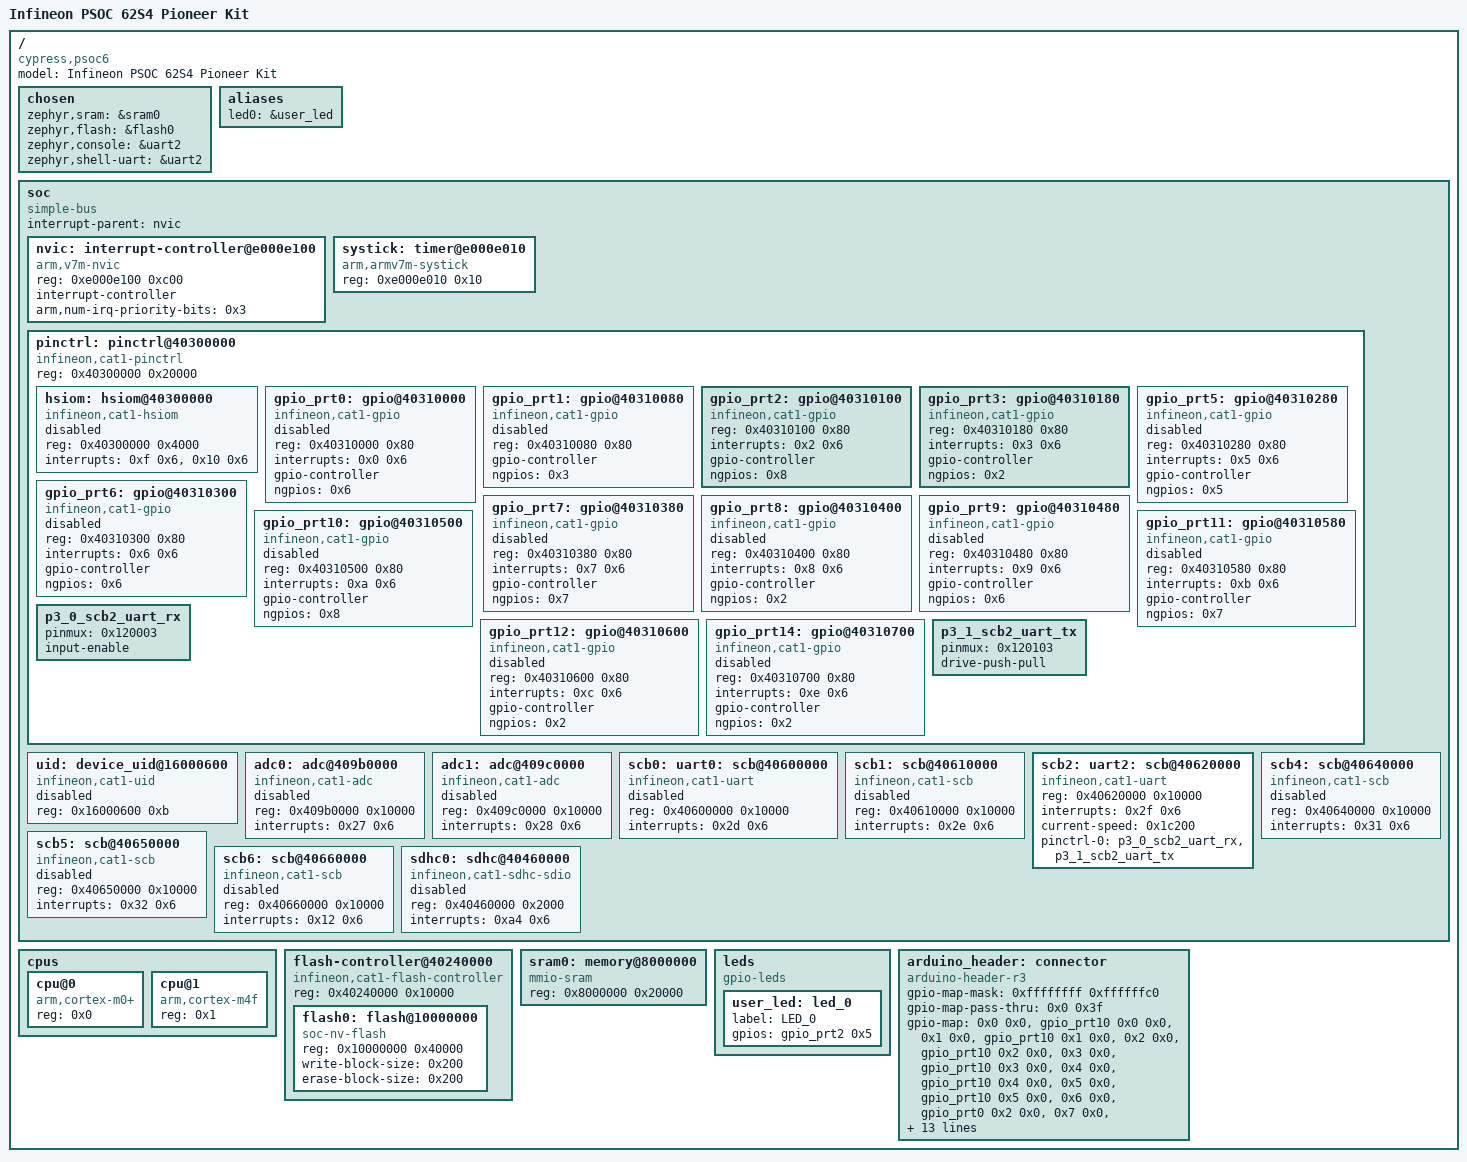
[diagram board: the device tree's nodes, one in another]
/dts-v1/;

/* node '/' defined in zephyr/dts/common/skeleton.dtsi:9 */
/ {
	#address-cells = < 0x1 >;                 /* in zephyr/dts/common/skeleton.dtsi:10 */
	#size-cells = < 0x1 >;                    /* in zephyr/dts/common/skeleton.dtsi:11 */
	model = "Infineon PSOC 62S4 Pioneer Kit"; /* in zephyr/boards/infineon/cy8ckit_062s4/cy8ckit_062s4.dts:11 */
	compatible = "cypress,psoc6";             /* in zephyr/boards/infineon/cy8ckit_062s4/cy8ckit_062s4.dts:12 */

	/* node '/chosen' defined in zephyr/dts/common/skeleton.dtsi:13 */
	chosen {
		zephyr,sram = &sram0;       /* in zephyr/boards/infineon/cy8ckit_062s4/cy8ckit_062s4.dts:15 */
		zephyr,flash = &flash0;     /* in zephyr/boards/infineon/cy8ckit_062s4/cy8ckit_062s4.dts:16 */
		zephyr,console = &uart2;    /* in zephyr/boards/infineon/cy8ckit_062s4/cy8ckit_062s4.dts:17 */
		zephyr,shell-uart = &uart2; /* in zephyr/boards/infineon/cy8ckit_062s4/cy8ckit_062s4.dts:18 */
	};

	/* node '/aliases' defined in zephyr/dts/common/skeleton.dtsi:15 */
	aliases {
		led0 = &user_led; /* in zephyr/boards/infineon/cy8ckit_062s4/cy8ckit_062s4.dts:22 */
	};

	/* node '/soc' defined in zephyr/dts/arm/armv7-m.dtsi:6 */
	soc {
		#address-cells = < 0x1 >;     /* in zephyr/dts/arm/armv7-m.dtsi:7 */
		#size-cells = < 0x1 >;        /* in zephyr/dts/arm/armv7-m.dtsi:8 */
		compatible = "simple-bus";    /* in zephyr/dts/arm/armv7-m.dtsi:9 */
		interrupt-parent = < &nvic >; /* in zephyr/dts/arm/armv7-m.dtsi:10 */
		ranges;                       /* in zephyr/dts/arm/armv7-m.dtsi:11 */

		/* node '/soc/interrupt-controller@e000e100' defined in zephyr/dts/arm/armv7-m.dtsi:13 */
		nvic: interrupt-controller@e000e100 {
			#address-cells = < 0x1 >;            /* in zephyr/dts/arm/armv7-m.dtsi:14 */
			compatible = "arm,v7m-nvic";         /* in zephyr/dts/arm/armv7-m.dtsi:15 */
			reg = < 0xe000e100 0xc00 >;          /* in zephyr/dts/arm/armv7-m.dtsi:16 */
			interrupt-controller;                /* in zephyr/dts/arm/armv7-m.dtsi:17 */
			#interrupt-cells = < 0x2 >;          /* in zephyr/dts/arm/armv7-m.dtsi:18 */
			arm,num-irq-priority-bits = < 0x3 >; /* in zephyr/dts/arm/infineon/cat1a/mpns/CY8C6244LQI_S4D92.dtsi:14 */
			phandle = < 0x1 >;                   /* in zephyr/dts/arm/armv7-m.dtsi:10 */
		};

		/* node '/soc/timer@e000e010' defined in zephyr/dts/arm/armv7-m.dtsi:21 */
		systick: timer@e000e010 {
			compatible = "arm,armv7m-systick"; /* in zephyr/dts/arm/armv7-m.dtsi:22 */
			reg = < 0xe000e010 0x10 >;         /* in zephyr/dts/arm/armv7-m.dtsi:23 */
		};

		/* node '/soc/pinctrl@40300000' defined in zephyr/dts/arm/infineon/cat1a/psoc6_04/psoc6_04.dtsi:55 */
		pinctrl: pinctrl@40300000 {
			compatible = "infineon,cat1-pinctrl"; /* in zephyr/dts/arm/infineon/cat1a/psoc6_04/psoc6_04.dtsi:56 */
			reg = < 0x40300000 0x20000 >;         /* in zephyr/dts/arm/infineon/cat1a/psoc6_04/psoc6_04.dtsi:57 */
			#address-cells = < 0x1 >;             /* in zephyr/dts/arm/infineon/cat1a/psoc6_04/psoc6_04.dtsi:58 */
			#size-cells = < 0x0 >;                /* in zephyr/dts/arm/infineon/cat1a/psoc6_04/psoc6_04.dtsi:59 */

			/* node '/soc/pinctrl@40300000/hsiom@40300000' defined in zephyr/dts/arm/infineon/cat1a/psoc6_04/psoc6_04.dtsi:61 */
			hsiom: hsiom@40300000 {
				compatible = "infineon,cat1-hsiom"; /* in zephyr/dts/arm/infineon/cat1a/psoc6_04/psoc6_04.dtsi:62 */
				reg = < 0x40300000 0x4000 >;        /* in zephyr/dts/arm/infineon/cat1a/psoc6_04/psoc6_04.dtsi:63 */
				interrupts = < 0xf 0x6 >,
				             < 0x10 0x6 >;          /* in zephyr/dts/arm/infineon/cat1a/psoc6_04/psoc6_04.dtsi:64 */
				status = "disabled";                /* in zephyr/dts/arm/infineon/cat1a/psoc6_04/psoc6_04.dtsi:65 */
			};

			/* node '/soc/pinctrl@40300000/gpio@40310000' defined in zephyr/dts/arm/infineon/cat1a/psoc6_04/psoc6_04.dtsi:68 */
			gpio_prt0: gpio@40310000 {
				compatible = "infineon,cat1-gpio"; /* in zephyr/dts/arm/infineon/cat1a/psoc6_04/psoc6_04.dtsi:69 */
				reg = < 0x40310000 0x80 >;         /* in zephyr/dts/arm/infineon/cat1a/psoc6_04/psoc6_04.dtsi:70 */
				interrupts = < 0x0 0x6 >;          /* in zephyr/dts/arm/infineon/cat1a/psoc6_04/psoc6_04.dtsi:71 */
				gpio-controller;                   /* in zephyr/dts/arm/infineon/cat1a/psoc6_04/psoc6_04.dtsi:72 */
				ngpios = < 0x6 >;                  /* in zephyr/dts/arm/infineon/cat1a/psoc6_04/psoc6_04.dtsi:73 */
				status = "disabled";               /* in zephyr/dts/arm/infineon/cat1a/psoc6_04/psoc6_04.dtsi:74 */
				#gpio-cells = < 0x2 >;             /* in zephyr/dts/arm/infineon/cat1a/psoc6_04/psoc6_04.dtsi:75 */
				phandle = < 0x6 >;                 /* in zephyr/boards/infineon/cy8ckit_062s4/cy8ckit_062s4.dts:39 */
			};

			/* node '/soc/pinctrl@40300000/gpio@40310080' defined in zephyr/dts/arm/infineon/cat1a/psoc6_04/psoc6_04.dtsi:78 */
			gpio_prt1: gpio@40310080 {
				compatible = "infineon,cat1-gpio"; /* in zephyr/dts/arm/infineon/cat1a/psoc6_04/psoc6_04.dtsi:79 */
				reg = < 0x40310080 0x80 >;         /* in zephyr/dts/arm/infineon/cat1a/psoc6_04/psoc6_04.dtsi:80 */
				gpio-controller;                   /* in zephyr/dts/arm/infineon/cat1a/psoc6_04/psoc6_04.dtsi:81 */
				ngpios = < 0x3 >;                  /* in zephyr/dts/arm/infineon/cat1a/psoc6_04/psoc6_04.dtsi:82 */
				status = "disabled";               /* in zephyr/dts/arm/infineon/cat1a/psoc6_04/psoc6_04.dtsi:83 */
				#gpio-cells = < 0x2 >;             /* in zephyr/dts/arm/infineon/cat1a/psoc6_04/psoc6_04.dtsi:84 */
			};

			/* node '/soc/pinctrl@40300000/gpio@40310100' defined in zephyr/dts/arm/infineon/cat1a/psoc6_04/psoc6_04.dtsi:87 */
			gpio_prt2: gpio@40310100 {
				compatible = "infineon,cat1-gpio"; /* in zephyr/dts/arm/infineon/cat1a/psoc6_04/psoc6_04.dtsi:88 */
				reg = < 0x40310100 0x80 >;         /* in zephyr/dts/arm/infineon/cat1a/psoc6_04/psoc6_04.dtsi:89 */
				interrupts = < 0x2 0x6 >;          /* in zephyr/dts/arm/infineon/cat1a/psoc6_04/psoc6_04.dtsi:90 */
				gpio-controller;                   /* in zephyr/dts/arm/infineon/cat1a/psoc6_04/psoc6_04.dtsi:91 */
				ngpios = < 0x8 >;                  /* in zephyr/dts/arm/infineon/cat1a/psoc6_04/psoc6_04.dtsi:92 */
				#gpio-cells = < 0x2 >;             /* in zephyr/dts/arm/infineon/cat1a/psoc6_04/psoc6_04.dtsi:94 */
				status = "okay";                   /* in zephyr/boards/infineon/cy8ckit_062s4/cy8ckit_062s4.dts:83 */
				phandle = < 0x4 >;                 /* in zephyr/boards/infineon/cy8ckit_062s4/cy8ckit_062s4.dts:30 */
			};

			/* node '/soc/pinctrl@40300000/gpio@40310180' defined in zephyr/dts/arm/infineon/cat1a/psoc6_04/psoc6_04.dtsi:97 */
			gpio_prt3: gpio@40310180 {
				compatible = "infineon,cat1-gpio"; /* in zephyr/dts/arm/infineon/cat1a/psoc6_04/psoc6_04.dtsi:98 */
				reg = < 0x40310180 0x80 >;         /* in zephyr/dts/arm/infineon/cat1a/psoc6_04/psoc6_04.dtsi:99 */
				interrupts = < 0x3 0x6 >;          /* in zephyr/dts/arm/infineon/cat1a/psoc6_04/psoc6_04.dtsi:100 */
				gpio-controller;                   /* in zephyr/dts/arm/infineon/cat1a/psoc6_04/psoc6_04.dtsi:101 */
				ngpios = < 0x2 >;                  /* in zephyr/dts/arm/infineon/cat1a/psoc6_04/psoc6_04.dtsi:102 */
				#gpio-cells = < 0x2 >;             /* in zephyr/dts/arm/infineon/cat1a/psoc6_04/psoc6_04.dtsi:104 */
				status = "okay";                   /* in zephyr/boards/infineon/cy8ckit_062s4/cy8ckit_062s4.dts:79 */
			};

			/* node '/soc/pinctrl@40300000/gpio@40310280' defined in zephyr/dts/arm/infineon/cat1a/psoc6_04/psoc6_04.dtsi:107 */
			gpio_prt5: gpio@40310280 {
				compatible = "infineon,cat1-gpio"; /* in zephyr/dts/arm/infineon/cat1a/psoc6_04/psoc6_04.dtsi:108 */
				reg = < 0x40310280 0x80 >;         /* in zephyr/dts/arm/infineon/cat1a/psoc6_04/psoc6_04.dtsi:109 */
				interrupts = < 0x5 0x6 >;          /* in zephyr/dts/arm/infineon/cat1a/psoc6_04/psoc6_04.dtsi:110 */
				gpio-controller;                   /* in zephyr/dts/arm/infineon/cat1a/psoc6_04/psoc6_04.dtsi:111 */
				ngpios = < 0x5 >;                  /* in zephyr/dts/arm/infineon/cat1a/psoc6_04/psoc6_04.dtsi:112 */
				status = "disabled";               /* in zephyr/dts/arm/infineon/cat1a/psoc6_04/psoc6_04.dtsi:113 */
				#gpio-cells = < 0x2 >;             /* in zephyr/dts/arm/infineon/cat1a/psoc6_04/psoc6_04.dtsi:114 */
				phandle = < 0x7 >;                 /* in zephyr/boards/infineon/cy8ckit_062s4/cy8ckit_062s4.dts:39 */
			};

			/* node '/soc/pinctrl@40300000/gpio@40310300' defined in zephyr/dts/arm/infineon/cat1a/psoc6_04/psoc6_04.dtsi:117 */
			gpio_prt6: gpio@40310300 {
				compatible = "infineon,cat1-gpio"; /* in zephyr/dts/arm/infineon/cat1a/psoc6_04/psoc6_04.dtsi:118 */
				reg = < 0x40310300 0x80 >;         /* in zephyr/dts/arm/infineon/cat1a/psoc6_04/psoc6_04.dtsi:119 */
				interrupts = < 0x6 0x6 >;          /* in zephyr/dts/arm/infineon/cat1a/psoc6_04/psoc6_04.dtsi:120 */
				gpio-controller;                   /* in zephyr/dts/arm/infineon/cat1a/psoc6_04/psoc6_04.dtsi:121 */
				ngpios = < 0x6 >;                  /* in zephyr/dts/arm/infineon/cat1a/psoc6_04/psoc6_04.dtsi:122 */
				status = "disabled";               /* in zephyr/dts/arm/infineon/cat1a/psoc6_04/psoc6_04.dtsi:123 */
				#gpio-cells = < 0x2 >;             /* in zephyr/dts/arm/infineon/cat1a/psoc6_04/psoc6_04.dtsi:124 */
				phandle = < 0x8 >;                 /* in zephyr/boards/infineon/cy8ckit_062s4/cy8ckit_062s4.dts:39 */
			};

			/* node '/soc/pinctrl@40300000/gpio@40310380' defined in zephyr/dts/arm/infineon/cat1a/psoc6_04/psoc6_04.dtsi:127 */
			gpio_prt7: gpio@40310380 {
				compatible = "infineon,cat1-gpio"; /* in zephyr/dts/arm/infineon/cat1a/psoc6_04/psoc6_04.dtsi:128 */
				reg = < 0x40310380 0x80 >;         /* in zephyr/dts/arm/infineon/cat1a/psoc6_04/psoc6_04.dtsi:129 */
				interrupts = < 0x7 0x6 >;          /* in zephyr/dts/arm/infineon/cat1a/psoc6_04/psoc6_04.dtsi:130 */
				gpio-controller;                   /* in zephyr/dts/arm/infineon/cat1a/psoc6_04/psoc6_04.dtsi:131 */
				ngpios = < 0x7 >;                  /* in zephyr/dts/arm/infineon/cat1a/psoc6_04/psoc6_04.dtsi:132 */
				status = "disabled";               /* in zephyr/dts/arm/infineon/cat1a/psoc6_04/psoc6_04.dtsi:133 */
				#gpio-cells = < 0x2 >;             /* in zephyr/dts/arm/infineon/cat1a/psoc6_04/psoc6_04.dtsi:134 */
			};

			/* node '/soc/pinctrl@40300000/gpio@40310400' defined in zephyr/dts/arm/infineon/cat1a/psoc6_04/psoc6_04.dtsi:137 */
			gpio_prt8: gpio@40310400 {
				compatible = "infineon,cat1-gpio"; /* in zephyr/dts/arm/infineon/cat1a/psoc6_04/psoc6_04.dtsi:138 */
				reg = < 0x40310400 0x80 >;         /* in zephyr/dts/arm/infineon/cat1a/psoc6_04/psoc6_04.dtsi:139 */
				interrupts = < 0x8 0x6 >;          /* in zephyr/dts/arm/infineon/cat1a/psoc6_04/psoc6_04.dtsi:140 */
				gpio-controller;                   /* in zephyr/dts/arm/infineon/cat1a/psoc6_04/psoc6_04.dtsi:141 */
				ngpios = < 0x2 >;                  /* in zephyr/dts/arm/infineon/cat1a/psoc6_04/psoc6_04.dtsi:142 */
				status = "disabled";               /* in zephyr/dts/arm/infineon/cat1a/psoc6_04/psoc6_04.dtsi:143 */
				#gpio-cells = < 0x2 >;             /* in zephyr/dts/arm/infineon/cat1a/psoc6_04/psoc6_04.dtsi:144 */
			};

			/* node '/soc/pinctrl@40300000/gpio@40310480' defined in zephyr/dts/arm/infineon/cat1a/psoc6_04/psoc6_04.dtsi:147 */
			gpio_prt9: gpio@40310480 {
				compatible = "infineon,cat1-gpio"; /* in zephyr/dts/arm/infineon/cat1a/psoc6_04/psoc6_04.dtsi:148 */
				reg = < 0x40310480 0x80 >;         /* in zephyr/dts/arm/infineon/cat1a/psoc6_04/psoc6_04.dtsi:149 */
				interrupts = < 0x9 0x6 >;          /* in zephyr/dts/arm/infineon/cat1a/psoc6_04/psoc6_04.dtsi:150 */
				gpio-controller;                   /* in zephyr/dts/arm/infineon/cat1a/psoc6_04/psoc6_04.dtsi:151 */
				ngpios = < 0x6 >;                  /* in zephyr/dts/arm/infineon/cat1a/psoc6_04/psoc6_04.dtsi:152 */
				status = "disabled";               /* in zephyr/dts/arm/infineon/cat1a/psoc6_04/psoc6_04.dtsi:153 */
				#gpio-cells = < 0x2 >;             /* in zephyr/dts/arm/infineon/cat1a/psoc6_04/psoc6_04.dtsi:154 */
			};

			/* node '/soc/pinctrl@40300000/gpio@40310500' defined in zephyr/dts/arm/infineon/cat1a/psoc6_04/psoc6_04.dtsi:157 */
			gpio_prt10: gpio@40310500 {
				compatible = "infineon,cat1-gpio"; /* in zephyr/dts/arm/infineon/cat1a/psoc6_04/psoc6_04.dtsi:158 */
				reg = < 0x40310500 0x80 >;         /* in zephyr/dts/arm/infineon/cat1a/psoc6_04/psoc6_04.dtsi:159 */
				interrupts = < 0xa 0x6 >;          /* in zephyr/dts/arm/infineon/cat1a/psoc6_04/psoc6_04.dtsi:160 */
				gpio-controller;                   /* in zephyr/dts/arm/infineon/cat1a/psoc6_04/psoc6_04.dtsi:161 */
				ngpios = < 0x8 >;                  /* in zephyr/dts/arm/infineon/cat1a/psoc6_04/psoc6_04.dtsi:162 */
				status = "disabled";               /* in zephyr/dts/arm/infineon/cat1a/psoc6_04/psoc6_04.dtsi:163 */
				#gpio-cells = < 0x2 >;             /* in zephyr/dts/arm/infineon/cat1a/psoc6_04/psoc6_04.dtsi:164 */
				phandle = < 0x5 >;                 /* in zephyr/boards/infineon/cy8ckit_062s4/cy8ckit_062s4.dts:39 */
			};

			/* node '/soc/pinctrl@40300000/gpio@40310580' defined in zephyr/dts/arm/infineon/cat1a/psoc6_04/psoc6_04.dtsi:167 */
			gpio_prt11: gpio@40310580 {
				compatible = "infineon,cat1-gpio"; /* in zephyr/dts/arm/infineon/cat1a/psoc6_04/psoc6_04.dtsi:168 */
				reg = < 0x40310580 0x80 >;         /* in zephyr/dts/arm/infineon/cat1a/psoc6_04/psoc6_04.dtsi:169 */
				interrupts = < 0xb 0x6 >;          /* in zephyr/dts/arm/infineon/cat1a/psoc6_04/psoc6_04.dtsi:170 */
				gpio-controller;                   /* in zephyr/dts/arm/infineon/cat1a/psoc6_04/psoc6_04.dtsi:171 */
				ngpios = < 0x7 >;                  /* in zephyr/dts/arm/infineon/cat1a/psoc6_04/psoc6_04.dtsi:172 */
				status = "disabled";               /* in zephyr/dts/arm/infineon/cat1a/psoc6_04/psoc6_04.dtsi:173 */
				#gpio-cells = < 0x2 >;             /* in zephyr/dts/arm/infineon/cat1a/psoc6_04/psoc6_04.dtsi:174 */
			};

			/* node '/soc/pinctrl@40300000/gpio@40310600' defined in zephyr/dts/arm/infineon/cat1a/psoc6_04/psoc6_04.dtsi:177 */
			gpio_prt12: gpio@40310600 {
				compatible = "infineon,cat1-gpio"; /* in zephyr/dts/arm/infineon/cat1a/psoc6_04/psoc6_04.dtsi:178 */
				reg = < 0x40310600 0x80 >;         /* in zephyr/dts/arm/infineon/cat1a/psoc6_04/psoc6_04.dtsi:179 */
				interrupts = < 0xc 0x6 >;          /* in zephyr/dts/arm/infineon/cat1a/psoc6_04/psoc6_04.dtsi:180 */
				gpio-controller;                   /* in zephyr/dts/arm/infineon/cat1a/psoc6_04/psoc6_04.dtsi:181 */
				ngpios = < 0x2 >;                  /* in zephyr/dts/arm/infineon/cat1a/psoc6_04/psoc6_04.dtsi:182 */
				status = "disabled";               /* in zephyr/dts/arm/infineon/cat1a/psoc6_04/psoc6_04.dtsi:183 */
				#gpio-cells = < 0x2 >;             /* in zephyr/dts/arm/infineon/cat1a/psoc6_04/psoc6_04.dtsi:184 */
			};

			/* node '/soc/pinctrl@40300000/gpio@40310700' defined in zephyr/dts/arm/infineon/cat1a/psoc6_04/psoc6_04.dtsi:187 */
			gpio_prt14: gpio@40310700 {
				compatible = "infineon,cat1-gpio"; /* in zephyr/dts/arm/infineon/cat1a/psoc6_04/psoc6_04.dtsi:188 */
				reg = < 0x40310700 0x80 >;         /* in zephyr/dts/arm/infineon/cat1a/psoc6_04/psoc6_04.dtsi:189 */
				interrupts = < 0xe 0x6 >;          /* in zephyr/dts/arm/infineon/cat1a/psoc6_04/psoc6_04.dtsi:190 */
				gpio-controller;                   /* in zephyr/dts/arm/infineon/cat1a/psoc6_04/psoc6_04.dtsi:191 */
				ngpios = < 0x2 >;                  /* in zephyr/dts/arm/infineon/cat1a/psoc6_04/psoc6_04.dtsi:192 */
				status = "disabled";               /* in zephyr/dts/arm/infineon/cat1a/psoc6_04/psoc6_04.dtsi:193 */
				#gpio-cells = < 0x2 >;             /* in zephyr/dts/arm/infineon/cat1a/psoc6_04/psoc6_04.dtsi:194 */
			};

			/* node '/soc/pinctrl@40300000/p3_0_scb2_uart_rx' defined in zephyr/dts/arm/infineon/cat1a/psoc6_04/psoc6_04.68-qfn.dtsi:152 */
			p3_0_scb2_uart_rx: p3_0_scb2_uart_rx {
				pinmux = < 0x120003 >; /* in zephyr/dts/arm/infineon/cat1a/psoc6_04/psoc6_04.68-qfn.dtsi:153 */
				input-enable;          /* in zephyr/boards/infineon/cy8ckit_062s4/cy8ckit_062s4.dts:67 */
				phandle = < 0x2 >;     /* in zephyr/boards/infineon/cy8ckit_062s4/cy8ckit_062s4.dts:74 */
			};

			/* node '/soc/pinctrl@40300000/p3_1_scb2_uart_tx' defined in zephyr/dts/arm/infineon/cat1a/psoc6_04/psoc6_04.68-qfn.dtsi:185 */
			p3_1_scb2_uart_tx: p3_1_scb2_uart_tx {
				pinmux = < 0x120103 >; /* in zephyr/dts/arm/infineon/cat1a/psoc6_04/psoc6_04.68-qfn.dtsi:186 */
				drive-push-pull;       /* in zephyr/boards/infineon/cy8ckit_062s4/cy8ckit_062s4.dts:63 */
				phandle = < 0x3 >;     /* in zephyr/boards/infineon/cy8ckit_062s4/cy8ckit_062s4.dts:74 */
			};
		};

		/* node '/soc/device_uid@16000600' defined in zephyr/dts/arm/infineon/cat1a/psoc6_04/psoc6_04.dtsi:198 */
		uid: device_uid@16000600 {
			compatible = "infineon,cat1-uid"; /* in zephyr/dts/arm/infineon/cat1a/psoc6_04/psoc6_04.dtsi:199 */
			reg = < 0x16000600 0xb >;         /* in zephyr/dts/arm/infineon/cat1a/psoc6_04/psoc6_04.dtsi:200 */
			status = "disabled";              /* in zephyr/dts/arm/infineon/cat1a/psoc6_04/psoc6_04.dtsi:201 */
		};

		/* node '/soc/adc@409b0000' defined in zephyr/dts/arm/infineon/cat1a/psoc6_04/psoc6_04.dtsi:204 */
		adc0: adc@409b0000 {
			compatible = "infineon,cat1-adc"; /* in zephyr/dts/arm/infineon/cat1a/psoc6_04/psoc6_04.dtsi:205 */
			reg = < 0x409b0000 0x10000 >;     /* in zephyr/dts/arm/infineon/cat1a/psoc6_04/psoc6_04.dtsi:206 */
			interrupts = < 0x27 0x6 >;        /* in zephyr/dts/arm/infineon/cat1a/psoc6_04/psoc6_04.dtsi:207 */
			status = "disabled";              /* in zephyr/dts/arm/infineon/cat1a/psoc6_04/psoc6_04.dtsi:208 */
		};

		/* node '/soc/adc@409c0000' defined in zephyr/dts/arm/infineon/cat1a/psoc6_04/psoc6_04.dtsi:211 */
		adc1: adc@409c0000 {
			compatible = "infineon,cat1-adc"; /* in zephyr/dts/arm/infineon/cat1a/psoc6_04/psoc6_04.dtsi:212 */
			reg = < 0x409c0000 0x10000 >;     /* in zephyr/dts/arm/infineon/cat1a/psoc6_04/psoc6_04.dtsi:213 */
			interrupts = < 0x28 0x6 >;        /* in zephyr/dts/arm/infineon/cat1a/psoc6_04/psoc6_04.dtsi:214 */
			status = "disabled";              /* in zephyr/dts/arm/infineon/cat1a/psoc6_04/psoc6_04.dtsi:215 */
		};

		/* node '/soc/scb@40600000' defined in zephyr/dts/arm/infineon/cat1a/psoc6_04/psoc6_04.dtsi:218 */
		scb0: uart0: arduino_serial: scb@40600000 {
			reg = < 0x40600000 0x10000 >;      /* in zephyr/dts/arm/infineon/cat1a/psoc6_04/psoc6_04.dtsi:220 */
			#address-cells = < 0x1 >;          /* in zephyr/dts/arm/infineon/cat1a/psoc6_04/psoc6_04.dtsi:221 */
			#size-cells = < 0x0 >;             /* in zephyr/dts/arm/infineon/cat1a/psoc6_04/psoc6_04.dtsi:222 */
			interrupts = < 0x2d 0x6 >;         /* in zephyr/dts/arm/infineon/cat1a/psoc6_04/psoc6_04.dtsi:223 */
			status = "disabled";               /* in zephyr/dts/arm/infineon/cat1a/psoc6_04/psoc6_04.dtsi:224 */
			compatible = "infineon,cat1-uart"; /* in zephyr/boards/infineon/cy8ckit_062s4/cy8ckit_062s4.dts:87 */
		};

		/* node '/soc/scb@40610000' defined in zephyr/dts/arm/infineon/cat1a/psoc6_04/psoc6_04.dtsi:227 */
		scb1: scb@40610000 {
			compatible = "infineon,cat1-scb"; /* in zephyr/dts/arm/infineon/cat1a/psoc6_04/psoc6_04.dtsi:228 */
			reg = < 0x40610000 0x10000 >;     /* in zephyr/dts/arm/infineon/cat1a/psoc6_04/psoc6_04.dtsi:229 */
			#address-cells = < 0x1 >;         /* in zephyr/dts/arm/infineon/cat1a/psoc6_04/psoc6_04.dtsi:230 */
			#size-cells = < 0x0 >;            /* in zephyr/dts/arm/infineon/cat1a/psoc6_04/psoc6_04.dtsi:231 */
			interrupts = < 0x2e 0x6 >;        /* in zephyr/dts/arm/infineon/cat1a/psoc6_04/psoc6_04.dtsi:232 */
			status = "disabled";              /* in zephyr/dts/arm/infineon/cat1a/psoc6_04/psoc6_04.dtsi:233 */
		};

		/* node '/soc/scb@40620000' defined in zephyr/dts/arm/infineon/cat1a/psoc6_04/psoc6_04.dtsi:236 */
		scb2: uart2: scb@40620000 {
			reg = < 0x40620000 0x10000 >;                          /* in zephyr/dts/arm/infineon/cat1a/psoc6_04/psoc6_04.dtsi:238 */
			#address-cells = < 0x1 >;                              /* in zephyr/dts/arm/infineon/cat1a/psoc6_04/psoc6_04.dtsi:239 */
			#size-cells = < 0x0 >;                                 /* in zephyr/dts/arm/infineon/cat1a/psoc6_04/psoc6_04.dtsi:240 */
			interrupts = < 0x2f 0x6 >;                             /* in zephyr/dts/arm/infineon/cat1a/psoc6_04/psoc6_04.dtsi:241 */
			compatible = "infineon,cat1-uart";                     /* in zephyr/boards/infineon/cy8ckit_062s4/cy8ckit_062s4.dts:71 */
			status = "okay";                                       /* in zephyr/boards/infineon/cy8ckit_062s4/cy8ckit_062s4.dts:72 */
			current-speed = < 0x1c200 >;                           /* in zephyr/boards/infineon/cy8ckit_062s4/cy8ckit_062s4.dts:73 */
			pinctrl-0 = < &p3_0_scb2_uart_rx &p3_1_scb2_uart_tx >; /* in zephyr/boards/infineon/cy8ckit_062s4/cy8ckit_062s4.dts:74 */
			pinctrl-names = "default";                             /* in zephyr/boards/infineon/cy8ckit_062s4/cy8ckit_062s4.dts:75 */
		};

		/* node '/soc/scb@40640000' defined in zephyr/dts/arm/infineon/cat1a/psoc6_04/psoc6_04.dtsi:245 */
		scb4: scb@40640000 {
			compatible = "infineon,cat1-scb"; /* in zephyr/dts/arm/infineon/cat1a/psoc6_04/psoc6_04.dtsi:246 */
			reg = < 0x40640000 0x10000 >;     /* in zephyr/dts/arm/infineon/cat1a/psoc6_04/psoc6_04.dtsi:247 */
			#address-cells = < 0x1 >;         /* in zephyr/dts/arm/infineon/cat1a/psoc6_04/psoc6_04.dtsi:248 */
			#size-cells = < 0x0 >;            /* in zephyr/dts/arm/infineon/cat1a/psoc6_04/psoc6_04.dtsi:249 */
			interrupts = < 0x31 0x6 >;        /* in zephyr/dts/arm/infineon/cat1a/psoc6_04/psoc6_04.dtsi:250 */
			status = "disabled";              /* in zephyr/dts/arm/infineon/cat1a/psoc6_04/psoc6_04.dtsi:251 */
		};

		/* node '/soc/scb@40650000' defined in zephyr/dts/arm/infineon/cat1a/psoc6_04/psoc6_04.dtsi:254 */
		scb5: scb@40650000 {
			compatible = "infineon,cat1-scb"; /* in zephyr/dts/arm/infineon/cat1a/psoc6_04/psoc6_04.dtsi:255 */
			reg = < 0x40650000 0x10000 >;     /* in zephyr/dts/arm/infineon/cat1a/psoc6_04/psoc6_04.dtsi:256 */
			#address-cells = < 0x1 >;         /* in zephyr/dts/arm/infineon/cat1a/psoc6_04/psoc6_04.dtsi:257 */
			#size-cells = < 0x0 >;            /* in zephyr/dts/arm/infineon/cat1a/psoc6_04/psoc6_04.dtsi:258 */
			interrupts = < 0x32 0x6 >;        /* in zephyr/dts/arm/infineon/cat1a/psoc6_04/psoc6_04.dtsi:259 */
			status = "disabled";              /* in zephyr/dts/arm/infineon/cat1a/psoc6_04/psoc6_04.dtsi:260 */
		};

		/* node '/soc/scb@40660000' defined in zephyr/dts/arm/infineon/cat1a/psoc6_04/psoc6_04.dtsi:263 */
		scb6: scb@40660000 {
			compatible = "infineon,cat1-scb"; /* in zephyr/dts/arm/infineon/cat1a/psoc6_04/psoc6_04.dtsi:264 */
			reg = < 0x40660000 0x10000 >;     /* in zephyr/dts/arm/infineon/cat1a/psoc6_04/psoc6_04.dtsi:265 */
			#address-cells = < 0x1 >;         /* in zephyr/dts/arm/infineon/cat1a/psoc6_04/psoc6_04.dtsi:266 */
			#size-cells = < 0x0 >;            /* in zephyr/dts/arm/infineon/cat1a/psoc6_04/psoc6_04.dtsi:267 */
			interrupts = < 0x12 0x6 >;        /* in zephyr/dts/arm/infineon/cat1a/psoc6_04/psoc6_04.dtsi:268 */
			status = "disabled";              /* in zephyr/dts/arm/infineon/cat1a/psoc6_04/psoc6_04.dtsi:269 */
		};

		/* node '/soc/sdhc@40460000' defined in zephyr/dts/arm/infineon/cat1a/psoc6_04/psoc6_04.dtsi:272 */
		sdhc0: sdhc@40460000 {
			compatible = "infineon,cat1-sdhc-sdio"; /* in zephyr/dts/arm/infineon/cat1a/psoc6_04/psoc6_04.dtsi:273 */
			reg = < 0x40460000 0x2000 >;            /* in zephyr/dts/arm/infineon/cat1a/psoc6_04/psoc6_04.dtsi:274 */
			interrupts = < 0xa4 0x6 >;              /* in zephyr/dts/arm/infineon/cat1a/psoc6_04/psoc6_04.dtsi:275 */
			status = "disabled";                    /* in zephyr/dts/arm/infineon/cat1a/psoc6_04/psoc6_04.dtsi:276 */
		};
	};

	/* node '/cpus' defined in zephyr/dts/arm/infineon/cat1a/psoc6_04/psoc6_04.dtsi:11 */
	cpus {
		#address-cells = < 0x1 >; /* in zephyr/dts/arm/infineon/cat1a/psoc6_04/psoc6_04.dtsi:12 */
		#size-cells = < 0x0 >;    /* in zephyr/dts/arm/infineon/cat1a/psoc6_04/psoc6_04.dtsi:13 */

		/* node '/cpus/cpu@0' defined in zephyr/dts/arm/infineon/cat1a/psoc6_04/psoc6_04.dtsi:15 */
		cpu@0 {
			device_type = "cpu";           /* in zephyr/dts/arm/infineon/cat1a/psoc6_04/psoc6_04.dtsi:16 */
			compatible = "arm,cortex-m0+"; /* in zephyr/dts/arm/infineon/cat1a/psoc6_04/psoc6_04.dtsi:17 */
			reg = < 0x0 >;                 /* in zephyr/dts/arm/infineon/cat1a/psoc6_04/psoc6_04.dtsi:18 */
		};

		/* node '/cpus/cpu@1' defined in zephyr/dts/arm/infineon/cat1a/psoc6_04/psoc6_04.dtsi:21 */
		cpu@1 {
			device_type = "cpu";           /* in zephyr/dts/arm/infineon/cat1a/psoc6_04/psoc6_04.dtsi:22 */
			compatible = "arm,cortex-m4f"; /* in zephyr/dts/arm/infineon/cat1a/psoc6_04/psoc6_04.dtsi:23 */
			reg = < 0x1 >;                 /* in zephyr/dts/arm/infineon/cat1a/psoc6_04/psoc6_04.dtsi:24 */
		};
	};

	/* node '/flash-controller@40240000' defined in zephyr/dts/arm/infineon/cat1a/psoc6_04/psoc6_04.dtsi:28 */
	flash-controller@40240000 {
		compatible = "infineon,cat1-flash-controller"; /* in zephyr/dts/arm/infineon/cat1a/psoc6_04/psoc6_04.dtsi:29 */
		reg = < 0x40240000 0x10000 >;                  /* in zephyr/dts/arm/infineon/cat1a/psoc6_04/psoc6_04.dtsi:30 */
		#address-cells = < 0x1 >;                      /* in zephyr/dts/arm/infineon/cat1a/psoc6_04/psoc6_04.dtsi:31 */
		#size-cells = < 0x1 >;                         /* in zephyr/dts/arm/infineon/cat1a/psoc6_04/psoc6_04.dtsi:32 */

		/* node '/flash-controller@40240000/flash@10000000' defined in zephyr/dts/arm/infineon/cat1a/psoc6_04/psoc6_04.dtsi:34 */
		flash0: flash@10000000 {
			compatible = "soc-nv-flash";  /* in zephyr/dts/arm/infineon/cat1a/psoc6_04/psoc6_04.dtsi:35 */
			reg = < 0x10000000 0x40000 >; /* in zephyr/dts/arm/infineon/cat1a/psoc6_04/psoc6_04.dtsi:36 */
			write-block-size = < 0x200 >; /* in zephyr/dts/arm/infineon/cat1a/psoc6_04/psoc6_04.dtsi:37 */
			erase-block-size = < 0x200 >; /* in zephyr/dts/arm/infineon/cat1a/psoc6_04/psoc6_04.dtsi:38 */
		};
	};

	/* node '/memory@8000000' defined in zephyr/dts/arm/infineon/cat1a/psoc6_04/psoc6_04.dtsi:49 */
	sram0: memory@8000000 {
		compatible = "mmio-sram";    /* in zephyr/dts/arm/infineon/cat1a/psoc6_04/psoc6_04.dtsi:50 */
		reg = < 0x8000000 0x20000 >; /* in zephyr/dts/arm/infineon/cat1a/psoc6_04/psoc6_04.dtsi:51 */
	};

	/* node '/leds' defined in zephyr/boards/infineon/cy8ckit_062s4/cy8ckit_062s4.dts:25 */
	leds {
		compatible = "gpio-leds"; /* in zephyr/boards/infineon/cy8ckit_062s4/cy8ckit_062s4.dts:26 */

		/* node '/leds/led_0' defined in zephyr/boards/infineon/cy8ckit_062s4/cy8ckit_062s4.dts:28 */
		user_led: led_0 {
			label = "LED_0";                /* in zephyr/boards/infineon/cy8ckit_062s4/cy8ckit_062s4.dts:29 */
			gpios = < &gpio_prt2 0x5 0x0 >; /* in zephyr/boards/infineon/cy8ckit_062s4/cy8ckit_062s4.dts:30 */
		};
	};

	/* node '/connector' defined in zephyr/boards/infineon/cy8ckit_062s4/cy8ckit_062s4.dts:34 */
	arduino_header: connector {
		compatible = "arduino-header-r3";           /* in zephyr/boards/infineon/cy8ckit_062s4/cy8ckit_062s4.dts:35 */
		#gpio-cells = < 0x2 >;                      /* in zephyr/boards/infineon/cy8ckit_062s4/cy8ckit_062s4.dts:36 */
		gpio-map-mask = < 0xffffffff 0xffffffc0 >;  /* in zephyr/boards/infineon/cy8ckit_062s4/cy8ckit_062s4.dts:37 */
		gpio-map-pass-thru = < 0x0 0x3f >;          /* in zephyr/boards/infineon/cy8ckit_062s4/cy8ckit_062s4.dts:38 */
		gpio-map = < 0x0 0x0 &gpio_prt10 0x0 0x0 >,
		           < 0x1 0x0 &gpio_prt10 0x1 0x0 >,
		           < 0x2 0x0 &gpio_prt10 0x2 0x0 >,
		           < 0x3 0x0 &gpio_prt10 0x3 0x0 >,
		           < 0x4 0x0 &gpio_prt10 0x4 0x0 >,
		           < 0x5 0x0 &gpio_prt10 0x5 0x0 >,
		           < 0x6 0x0 &gpio_prt0 0x2 0x0 >,
		           < 0x7 0x0 &gpio_prt0 0x3 0x0 >,
		           < 0x8 0x0 &gpio_prt5 0x0 0x0 >,
		           < 0x9 0x0 &gpio_prt5 0x1 0x0 >,
		           < 0xa 0x0 &gpio_prt5 0x6 0x0 >,
		           < 0xb 0x0 &gpio_prt5 0x7 0x0 >,
		           < 0xc 0x0 &gpio_prt6 0x2 0x0 >,
		           < 0xd 0x0 &gpio_prt6 0x3 0x0 >,
		           < 0xe 0x0 &gpio_prt2 0x4 0x0 >,
		           < 0xf 0x0 &gpio_prt2 0x6 0x0 >,
		           < 0x10 0x0 &gpio_prt2 0x3 0x0 >,
		           < 0x11 0x0 &gpio_prt2 0x0 0x0 >,
		           < 0x12 0x0 &gpio_prt2 0x1 0x0 >,
		           < 0x13 0x0 &gpio_prt2 0x2 0x0 >; /* in zephyr/boards/infineon/cy8ckit_062s4/cy8ckit_062s4.dts:39 */
	};
};
